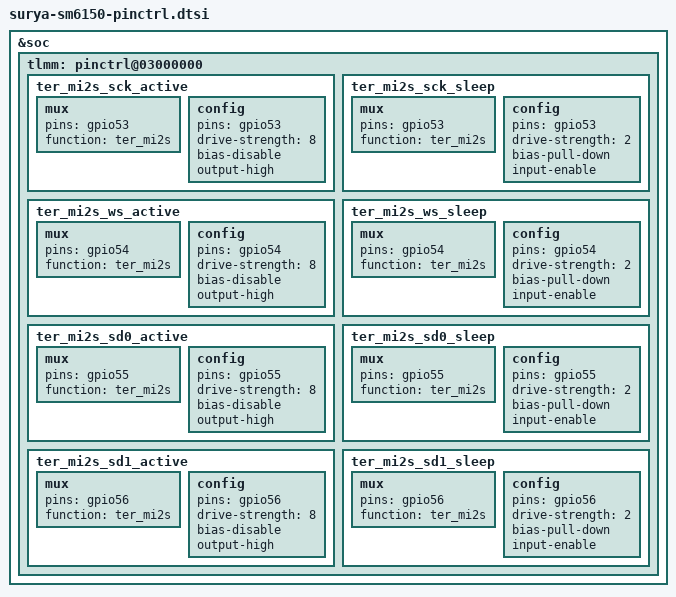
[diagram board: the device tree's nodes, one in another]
&soc {
	tlmm: pinctrl@03000000 {
		ter_mi2s_sck_active: ter_mi2s_sck_active {
			mux {
				pins = "gpio53";
				function = "ter_mi2s";
			};

			config {
				pins = "gpio53";
				drive-strength = <8>;
				bias-disable;
				output-high;
			};
		};

		ter_mi2s_sck_sleep: ter_mi2s_sck_sleep {
			mux {
				pins = "gpio53";
				function = "ter_mi2s";
			};

			config {
				pins = "gpio53";
				drive-strength = <2>;   /* 2 mA */
				bias-pull-down;         /* PULL DOWN */
				input-enable;

			};
		};

		ter_mi2s_ws_active: ter_mi2s_ws_active {
			mux {
				pins = "gpio54";
				function = "ter_mi2s";
			};

			config {
				pins = "gpio54";
				drive-strength = <8>;
				bias-disable;           /* NO PULL */
				output-high;
			};
		};

		ter_mi2s_ws_sleep: ter_mi2s_ws_sleep {
			mux {
				pins = "gpio54";
				function = "ter_mi2s";
			};

			config {
				pins = "gpio54";
				drive-strength = <2>;
				bias-pull-down;         /* PULL DOWN */
				input-enable;
			};
		};

		ter_mi2s_sd0_active: ter_mi2s_sd0_active {
			mux {
				pins = "gpio55";
				function = "ter_mi2s";
			};

			config {
				pins = "gpio55";
				drive-strength = <8>;
				bias-disable;           /* NO PULL */
				output-high;
			};
		};

		ter_mi2s_sd0_sleep: ter_mi2s_sd0_sleep {
			mux {
				pins = "gpio55";
				function = "ter_mi2s";
			};

			config {
				pins = "gpio55";
				drive-strength = <2>;
				bias-pull-down;         /* PULL DOWN */
				input-enable;
			};
		};

		ter_mi2s_sd1_active: ter_mi2s_sd1_active {
			mux {
				pins = "gpio56";
				function = "ter_mi2s";
			};

			config {
				pins = "gpio56";
				drive-strength = <8>;
				bias-disable;           /* NO PULL */
				output-high;
			};
		};

		ter_mi2s_sd1_sleep: ter_mi2s_sd1_sleep {
			mux {
				pins = "gpio56";
				function = "ter_mi2s";
			};

			config {
				pins = "gpio56";
				drive-strength = <2>;
				bias-pull-down;         /* PULL DOWN */
				input-enable;
			};
		};
	};
};
